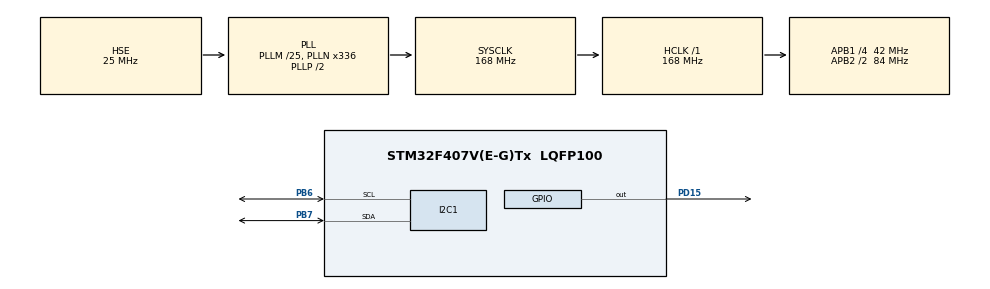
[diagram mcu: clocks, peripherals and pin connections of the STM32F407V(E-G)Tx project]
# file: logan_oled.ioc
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I2C1.I2C_Mode=I2C_Fast
Mcu.Family=STM32F4
Mcu.Name=STM32F407V(E-G)Tx
Mcu.Package=LQFP100
NVIC.PriorityGroup=NVIC_PRIORITYGROUP_4
PA13.Mode=Serial_Wire
PA13.Signal=SYS_JTMS-SWDIO
PA14.Mode=Serial_Wire
PA14.Signal=SYS_JTCK-SWCLK
PB6.Mode=I2C
PB6.Signal=I2C1_SCL
PB7.Mode=I2C
PB7.Signal=I2C1_SDA
PD15.Signal=GPIO_Output
PH0-OSC_IN.Mode=HSE-External-Oscillator
PH0-OSC_IN.Signal=RCC_OSC_IN
PH1-OSC_OUT.Mode=HSE-External-Oscillator
PH1-OSC_OUT.Signal=RCC_OSC_OUT
ProjectManager.HeapSize=0x200
ProjectManager.StackSize=0x400
ProjectManager.TargetToolchain=MDK-ARM V5.32
RCC.48MHZClocksFreq_Value=84000000
RCC.AHBFreq_Value=168000000
RCC.APB1CLKDivider=RCC_HCLK_DIV4
RCC.APB1Freq_Value=42000000
RCC.APB1TimFreq_Value=84000000
RCC.APB2CLKDivider=RCC_HCLK_DIV2
RCC.APB2Freq_Value=84000000
RCC.APB2TimFreq_Value=168000000
RCC.CortexFreq_Value=168000000
RCC.HCLKFreq_Value=168000000
RCC.HSE_VALUE=25000000
RCC.HSI_VALUE=16000000
RCC.LSE_VALUE=32768
RCC.PLLM=25
RCC.PLLN=336
RCC.PLLSourceVirtual=RCC_PLLSOURCE_HSE
RCC.SYSCLKFreq_VALUE=168000000
RCC.SYSCLKSource=RCC_SYSCLKSOURCE_PLLCLK
RCC.VCOOutputFreq_Value=336000000
board=custom

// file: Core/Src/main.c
/* USER CODE BEGIN Header */
/**
  ******************************************************************************
  * @file           : main.c
  * @brief          : Main program body
  ******************************************************************************
  * @attention
  *
  * Copyright (c) 2025 STMicroelectronics.
  * All rights reserved.
  *
  * This software is licensed under terms that can be found in the LICENSE file
  * in the root directory of this software component.
  * If no LICENSE file comes with this software, it is provided AS-IS.
  *
  ******************************************************************************
  */
/* USER CODE END Header */
#include "main.h"

/* USER CODE BEGIN Includes */
#include "stdio.h"
#include "font.h"
#include "oled_i2c.h"
/* USER CODE END Includes */

I2C_HandleTypeDef hi2c1;

void SystemClock_Config(void);
static void MX_GPIO_Init(void);
static void MX_I2C1_Init(void);

/* USER CODE BEGIN 0 */
const uint8_t smiley_face_128x64[1026] = {
    // H�ng 0-7
    0x00, 0x00, 0x00, 0x00, 0x00, 0x00, 0x00, 0x00, 0x00, 0x00, 0x00, 0x00, 0x00, 0x00, 0x00, 0x00,
    0x00, 0x00, 0x00, 0x00, 0x00, 0x00, 0x00, 0x00, 0x00, 0x00, 0x00, 0x00, 0x00, 0x00, 0x00, 0x00,
    0x00, 0x00, 0x00, 0x00, 0x00, 0x00, 0x00, 0x00, 0x00, 0x00, 0x00, 0x00, 0x00, 0x00, 0x00, 0x00,
    0x00, 0x00, 0x00, 0x00, 0x00, 0x00, 0x00, 0xFF, 0xFF, 0x00, 0x00, 0x00, 0x00, 0x00, 0x00, 0x00,
    0x00, 0x00, 0x00, 0x00, 0x00, 0x00, 0xFF, 0xFF, 0xFF, 0xFF, 0x00, 0x00, 0x00, 0x00, 0x00, 0x00,
    0x00, 0x00, 0x00, 0x00, 0x00, 0xFF, 0xFF, 0xFF, 0xFF, 0xFF, 0xFF, 0x00, 0x00, 0x00, 0x00, 0x00,
    0x00, 0x00, 0x00, 0x00, 0xFF, 0xFF, 0xFF, 0xFF, 0xFF, 0xFF, 0xFF, 0xFF, 0x00, 0x00, 0x00, 0x00,
    0x00, 0x00, 0x00, 0xFF, 0xFF, 0xFF, 0xFF, 0xFF, 0xFF, 0xFF, 0xFF, 0xFF, 0xFF, 0x00, 0x00, 0x00,

    // H�ng 8-15
    0x00, 0x00, 0x00, 0xFF, 0xFF, 0xFF, 0xFF, 0xFF, 0xFF, 0xFF, 0xFF, 0xFF, 0xFF, 0x00, 0x00, 0x00,
    0x00, 0x00, 0xFF, 0xFF, 0xFF, 0xFF, 0xFF, 0xFF, 0xFF, 0xFF, 0xFF, 0xFF, 0xFF, 0xFF, 0x00, 0x00,
    0x00, 0x00, 0xFF, 0xFF, 0xFF, 0xFF, 0xFF, 0xFF, 0xFF, 0xFF, 0xFF, 0xFF, 0xFF, 0xFF, 0x00, 0x00,
    0x00, 0xFF, 0xFF, 0xFF, 0xFF, 0xFF, 0xFF, 0xFF, 0xFF, 0xFF, 0xFF, 0xFF, 0xFF, 0xFF, 0xFF, 0x00,
    0x00, 0xFF, 0xFF, 0xFF, 0xFF, 0xFF, 0xFF, 0xFF, 0xFF, 0xFF, 0xFF, 0xFF, 0xFF, 0xFF, 0xFF, 0x00,
    0x00, 0xFF, 0xFF, 0xFF, 0xFF, 0xFF, 0xFF, 0xFF, 0xFF, 0xFF, 0xFF, 0xFF, 0xFF, 0xFF, 0xFF, 0x00,
    0x00, 0xFF, 0xFF, 0xFF, 0xFF, 0xFF, 0xFF, 0xFF, 0xFF, 0xFF, 0xFF, 0xFF, 0xFF, 0xFF, 0xFF, 0x00,
    0x00, 0xFF, 0xFF, 0xFF, 0xFF, 0xFF, 0xFF, 0xFF, 0xFF, 0xFF, 0xFF, 0xFF, 0xFF, 0xFF, 0xFF, 0x00,

    // H�ng 16-23 (Th�m m?t)
    0x00, 0xFF, 0xFF, 0xFF, 0xFF, 0xFF, 0xFF, 0xF0, 0x0F, 0xFF, 0xFF, 0xFF, 0xFF, 0xFF, 0xFF, 0x00,
    0x00, 0xFF, 0xFF, 0xFF, 0xFF, 0xFF, 0xF0, 0x00, 0x00, 0x0F, 0xFF, 0xFF, 0xFF, 0xFF, 0xFF, 0x00,
    0x00, 0xFF, 0xFF, 0xFF, 0xFF, 0xFF, 0xF0, 0x00, 0x00, 0x0F, 0xFF, 0xFF, 0xFF, 0xFF, 0xFF, 0x00,
    0x00, 0xFF, 0xFF, 0xFF, 0xFF, 0xFF, 0xF0, 0x00, 0x00, 0x0F, 0xFF, 0xFF, 0xFF, 0xFF, 0xFF, 0x00,
    0x00, 0xFF, 0xFF, 0xFF, 0xFF, 0xFF, 0xFF, 0xF0, 0x0F, 0xFF, 0xFF, 0xFF, 0xFF, 0xFF, 0xFF, 0x00,
    0x00, 0xFF, 0xFF, 0xFF, 0xFF, 0xFF, 0xFF, 0xFF, 0xFF, 0xFF, 0xFF, 0xFF, 0xFF, 0xFF, 0xFF, 0x00,
    0x00, 0xFF, 0xFF, 0xFF, 0xFF, 0xFF, 0xFF, 0xFF, 0xFF, 0xFF, 0xFF, 0xFF, 0xFF, 0xFF, 0xFF, 0x00,
    0x00, 0xFF, 0xFF, 0xFF, 0xFF, 0xFF, 0xFF, 0xFF, 0xFF, 0xFF, 0xFF, 0xFF, 0xFF, 0xFF, 0xFF, 0x00,

    // H�ng 24-31 (Th�m m?t)
    0x00, 0xFF, 0xFF, 0xFF, 0xFF, 0xFF, 0xFF, 0xFF, 0xFF, 0xFF, 0xFF, 0xFF, 0xFF, 0xFF, 0xFF, 0x00,
    0x00, 0xFF, 0xFF, 0xFF, 0xFF, 0xFF, 0xFF, 0xFF, 0xFF, 0xFF, 0xFF, 0xFF, 0xFF, 0xFF, 0xFF, 0x00,
    0x00, 0xFF, 0xFF, 0xFF, 0xFF, 0xFF, 0xFF, 0xFF, 0xFF, 0xFF, 0xFF, 0xFF, 0xFF, 0xFF, 0xFF, 0x00,
    0x00, 0xFF, 0xFF, 0xFF, 0xFF, 0xFF, 0xFF, 0xFF, 0xFF, 0xFF, 0xFF, 0xFF, 0xFF, 0xFF, 0xFF, 0x00,
    0x00, 0xFF, 0xFF, 0xFF, 0xFF, 0xFF, 0xFF, 0xFF, 0xFF, 0xFF, 0xFF, 0xFF, 0xFF, 0xFF, 0xFF, 0x00,
    0x00, 0xFF, 0xFF, 0xFF, 0xFF, 0xFF, 0xFF, 0xFF, 0xFF, 0xFF, 0xFF, 0xFF, 0xFF, 0xFF, 0xFF, 0x00,
    0x00, 0xFF, 0xFF, 0xFF, 0xFF, 0xFF, 0xFF, 0xFF, 0xFF, 0xFF, 0xFF, 0xFF, 0xFF, 0xFF, 0xFF, 0x00,
    0x00, 0xFF, 0xFF, 0xFF, 0xFF, 0xFF, 0xFF, 0xFF, 0xFF, 0xFF, 0xFF, 0xFF, 0xFF, 0xFF, 0xFF, 0x00,

    // H�ng 32-39 (Th�m mi?ng cu?i)
    0x00, 0xFF, 0xFF, 0xFF, 0xFF, 0xFF, 0xFF, 0xFF, 0xFF, 0xFF, 0xFF, 0xFF, 0xFF, 0xFF, 0xFF, 0x00,
    0x00, 0xFF, 0xFF, 0xFF, 0xFF, 0xFF, 0xFF, 0xFF, 0xFF, 0xFF, 0xFF, 0xFF, 0xFF, 0xFF, 0xFF, 0x00,
    0x00, 0xFF, 0xFF, 0xFF, 0xFF, 0xFF, 0xFF, 0xFF, 0xFF, 0xFF, 0xFF, 0xFF, 0xFF, 0xFF, 0xFF, 0x00,
    0x00, 0xFF, 0xFF, 0xFF, 0xFF, 0xFF, 0xFF, 0x00, 0x00, 0xFF, 0xFF, 0xFF, 0xFF, 0xFF, 0xFF, 0x00,
    0x00, 0xFF, 0xFF, 0xFF, 0xFF, 0xFF, 0xF0, 0x00, 0x00, 0x0F, 0xFF, 0xFF, 0xFF, 0xFF, 0xFF, 0x00,
    0x00, 0xFF, 0xFF, 0xFF, 0xFF, 0xFF, 0x00, 0x00, 0x00, 0x00, 0xFF, 0xFF, 0xFF, 0xFF, 0xFF, 0x00,
    0x00, 0xFF, 0xFF, 0xFF, 0xFF, 0xF0, 0x00, 0x00, 0x00, 0x00, 0x0F, 0xFF, 0xFF, 0xFF, 0xFF, 0x00,
    0x00, 0xFF, 0xFF, 0xFF, 0xFF, 0xF0, 0x00, 0x00, 0x00, 0x00, 0x0F, 0xFF, 0xFF, 0xFF, 0xFF, 0x00,

    // H�ng 40-47
    0x00, 0xFF, 0xFF, 0xFF, 0xFF, 0xFF, 0x00, 0x00, 0x00, 0x00, 0xFF, 0xFF, 0xFF, 0xFF, 0xFF, 0x00,
    0x00, 0xFF, 0xFF, 0xFF, 0xFF, 0xFF, 0xF0, 0x00, 0x00, 0x0F, 0xFF, 0xFF, 0xFF, 0xFF, 0xFF, 0x00,
    0x00, 0xFF, 0xFF, 0xFF, 0xFF, 0xFF, 0xFF, 0x00, 0x00, 0xFF, 0xFF, 0xFF, 0xFF, 0xFF, 0xFF, 0x00,
    0x00, 0xFF, 0xFF, 0xFF, 0xFF, 0xFF, 0xFF, 0xFF, 0xFF, 0xFF, 0xFF, 0xFF, 0xFF, 0xFF, 0xFF, 0x00,
    0x00, 0xFF, 0xFF, 0xFF, 0xFF, 0xFF, 0xFF, 0xFF, 0xFF, 0xFF, 0xFF, 0xFF, 0xFF, 0xFF, 0xFF, 0x00,
    0x00, 0xFF, 0xFF, 0xFF, 0xFF, 0xFF, 0xFF, 0xFF, 0xFF, 0xFF, 0xFF, 0xFF, 0xFF, 0xFF, 0xFF, 0x00,
    0x00, 0xFF, 0xFF, 0xFF, 0xFF, 0xFF, 0xFF, 0xFF, 0xFF, 0xFF, 0xFF, 0xFF, 0xFF, 0xFF, 0xFF, 0x00,
    0x00, 0xFF, 0xFF, 0xFF, 0xFF, 0xFF, 0xFF, 0xFF, 0xFF, 0xFF, 0xFF, 0xFF, 0xFF, 0xFF, 0xFF, 0x00,

    // H�ng 48-55
    0x00, 0xFF, 0xFF, 0xFF, 0xFF, 0xFF, 0xFF, 0xFF, 0xFF, 0xFF, 0xFF, 0xFF, 0xFF, 0xFF, 0xFF, 0x00,
    0x00, 0xFF, 0xFF, 0xFF, 0xFF, 0xFF, 0xFF, 0xFF, 0xFF, 0xFF, 0xFF, 0xFF, 0xFF, 0xFF, 0xFF, 0x00,
    0x00, 0x00, 0xFF, 0xFF, 0xFF, 0xFF, 0xFF, 0xFF, 0xFF, 0xFF, 0xFF, 0xFF, 0xFF, 0xFF, 0x00, 0x00,
    0x00, 0x00, 0xFF, 0xFF, 0xFF, 0xFF, 0xFF, 0xFF, 0xFF, 0xFF, 0xFF, 0xFF, 0xFF, 0xFF, 0x00, 0x00,
    0x00, 0x00, 0x00, 0xFF, 0xFF, 0xFF, 0xFF, 0xFF, 0xFF, 0xFF, 0xFF, 0xFF, 0xFF, 0x00, 0x00, 0x00,
    0x00, 0x00, 0x00, 0xFF, 0xFF, 0xFF, 0xFF, 0xFF, 0xFF, 0xFF, 0xFF, 0xFF, 0xFF, 0x00, 0x00, 0x00,
    0x00, 0x00, 0x00, 0x00, 0xFF, 0xFF, 0xFF, 0xFF, 0xFF, 0xFF, 0xFF, 0xFF, 0x00, 0x00, 0x00, 0x00,
    0x00,0x00, 0x00, 0x00, 0x00, 0xFF, 0xFF, 0xFF, 0xFF, 0xFF, 0xFF, 0xFF, 0xFF, 0x00, 0x00, 0x00, 0x00,

    // H�ng 56-63
    0x00, 0x00, 0x00, 0x00, 0x00, 0xFF, 0xFF, 0xFF, 0xFF, 0xFF, 0xFF, 0x00, 0x00, 0x00, 0x00, 0x00,
    0x00, 0x00, 0x00, 0x00, 0x00, 0x00, 0xFF, 0xFF, 0xFF, 0xFF, 0x00, 0x00, 0x00, 0x00, 0x00, 0x00,
    0x00, 0x00, 0x00, 0x00, 0x00, 0x00, 0x00, 0xFF, 0xFF, 0x00, 0x00, 0x00, 0x00, 0x00, 0x00, 0x00,
    0x00, 0x00, 0x00, 0x00, 0x00, 0x00, 0x00, 0x00, 0x00, 0x00, 0x00, 0x00, 0x00, 0x00, 0x00, 0x00,
    0x00, 0x00, 0x00, 0x00, 0x00, 0x00, 0x00, 0x00, 0x00, 0x00, 0x00, 0x00, 0x00, 0x00, 0x00, 0x00,
    0x00, 0x00, 0x00, 0x00, 0x00, 0x00, 0x00, 0x00, 0x00, 0x00, 0x00, 0x00, 0x00, 0x00, 0x00, 0x00,
    0x00, 0x00, 0x00, 0x00, 0x00, 0x00, 0x00, 0x00, 0x00, 0x00, 0x00, 0x00, 0x00, 0x00, 0x00, 0x00,
    0x00, 0x00, 0x00, 0x00, 0x00, 0x00, 0x00, 0x00, 0x00, 0x00, 0x00, 0x00, 0x00, 0x00, 0x00, 0x00
};

const uint8_t cat[10000] = {
	0xff,0xff,0xff,0xff,0xff,0xff,0xff,0xff,0xff,0xff,0xff,0xff,0xff,0xff,0xff,0xff
,0xff,0xff,0xff,0xff,0xff,0xff,0xff,0xff,0xff,0xff,0xff,0xff,0xff,0xff,0xff,0xff
,0xff,0xff,0xff,0xff,0xff,0xff,0xff,0xff,0xff,0xff,0xff,0xff,0xff,0xff,0xff,0xff
,0xff,0xff,0xff,0xff,0xff,0xff,0xff,0xfc,0x1f,0xff,0xff,0xff,0xff,0xff,0xff,0xff
,0xff,0xff,0xff,0xff,0xff,0xff,0xfc,0x00,0x00,0x1f,0xff,0xff,0xff,0xff,0xff,0xff
,0xff,0xff,0xff,0xff,0xff,0xff,0xc0,0x7f,0xfe,0x03,0xff,0xff,0xff,0xff,0xff,0xff
,0xff,0xff,0xff,0xff,0xff,0xff,0x07,0xff,0xff,0xf0,0x7f,0xff,0xff,0xff,0xff,0xff
,0xff,0xff,0xff,0xff,0xff,0xfc,0x3f,0xff,0xff,0xfe,0x1f,0xff,0xff,0xff,0xff,0xff
,0xff,0xff,0xff,0xff,0xff,0xf1,0xff,0xff,0xff,0xff,0x87,0xff,0xff,0xff,0xff,0xff
,0xff,0xff,0xff,0xff,0xff,0xe3,0xff,0xff,0xff,0xff,0xe3,0xff,0xff,0xff,0xff,0xff
,0xff,0xff,0xff,0xff,0xff,0xc7,0xff,0xff,0xff,0xff,0xf1,0xff,0xff,0xff,0xff,0xff
,0xff,0xff,0xff,0xff,0xff,0x8f,0xff,0xff,0xff,0xff,0xf8,0xff,0xff,0xff,0xff,0xff
,0xff,0xff,0xff,0xff,0xff,0x1f,0xff,0xff,0xff,0xff,0xfc,0x7f,0xff,0xff,0xff,0xff
,0xff,0xff,0xff,0xff,0xff,0x3f,0xff,0xff,0xff,0xff,0xfe,0x7f,0xff,0xff,0xff,0xff
,0xff,0xff,0xff,0xff,0xff,0x3f,0xff,0xff,0xff,0xff,0xfe,0x3f,0xff,0xff,0xff,0xff
,0xff,0xff,0xff,0xff,0xfe,0x3f,0xff,0xff,0xff,0xff,0xfe,0x3f,0xff,0xff,0xff,0xff
,0xff,0xff,0xff,0xff,0xff,0x3f,0xf0,0x1f,0xfc,0x07,0xfe,0x7f,0xff,0xff,0xff,0xff
,0xff,0xff,0xff,0xff,0xff,0x3f,0xc0,0x0f,0xf0,0x01,0xfe,0x7f,0xff,0xff,0xff,0xff
,0xff,0xff,0xef,0xff,0xff,0x1f,0xc0,0x07,0xf0,0x01,0xfc,0x7f,0xff,0xff,0xff,0xff
,0xff,0xff,0xff,0xff,0xff,0x8f,0xc0,0x07,0xf0,0x01,0xf8,0xff,0xff,0xff,0xff,0xff
,0xff,0xff,0xff,0xff,0xff,0xc7,0xc0,0x0f,0xf8,0x03,0xf1,0xff,0xff,0xff,0xff,0xff
,0xff,0xff,0xff,0xff,0xff,0xe3,0xe0,0x1f,0xfc,0x07,0xe3,0xff,0xff,0xff,0xff,0xff
,0xff,0xff,0xff,0xff,0xff,0xf1,0xff,0xf8,0x0f,0xff,0x87,0xff,0xff,0xff,0xff,0xff
,0xff,0xff,0xff,0xff,0xff,0xfc,0x3f,0xf8,0x0f,0xfe,0x1f,0xff,0xff,0xff,0xff,0xff
,0xff,0xff,0xff,0xff,0xff,0xff,0x07,0xfc,0x1f,0xf0,0x7f,0xff,0xff,0xff,0xff,0xff
,0xff,0xff,0xff,0xff,0xff,0xff,0xc3,0xfe,0x3f,0xe3,0xff,0xff,0xff,0xff,0xff,0xff
,0xff,0xff,0xff,0xff,0xff,0xff,0xe3,0xfe,0x7f,0xe7,0xff,0xff,0xff,0xff,0xff,0xff
,0xff,0xff,0xff,0xff,0xff,0xff,0xe3,0xff,0xff,0xc7,0xff,0xff,0xff,0xff,0xff,0xff
,0xff,0xff,0xff,0xff,0xff,0xff,0xe3,0xff,0xff,0xc7,0xff,0xff,0xff,0xff,0xff,0xff
,0xff,0xff,0xff,0xff,0xff,0xff,0xe3,0xdd,0xdd,0xc7,0xff,0xff,0xff,0xff,0xff,0xff
,0xff,0xff,0xff,0xff,0xff,0xff,0xe0,0x00,0x00,0x07,0xff,0xff,0xff,0xff,0xff,0xff
,0xff,0xff,0xff,0xff,0xff,0xff,0xf4,0xc4,0x00,0x0f,0xff,0xff,0xff,0xff,0xff,0xff
,0xff,0xff,0xff,0xff,0xff,0xff,0xfc,0xee,0x77,0x3f,0xff,0xff,0xff,0xff,0xff,0xff
,0xff,0xff,0xff,0xff,0xff,0xff,0xff,0xef,0x77,0xbf,0xff,0xff,0xff,0xff,0xff,0xff
,0xff,0xff,0xff,0xff,0xff,0xff,0xff,0xff,0xff,0xff,0xff,0xff,0xff,0xff,0xff,0xff
,0xff,0xff,0xff,0xff,0xff,0xc0,0xff,0x0f,0xe3,0xe1,0xe0,0x1f,0xff,0xff,0xff,0xff
,0xff,0xff,0xff,0xff,0xff,0x84,0x3f,0x03,0xe0,0xc1,0xe1,0xff,0xff,0xff,0xff,0xff
,0xff,0xff,0xff,0xff,0xff,0x86,0x3e,0x03,0xe0,0xc1,0xe3,0xff,0xff,0xff,0xff,0xff
,0xff,0xff,0xff,0xff,0xff,0x8f,0xfe,0x03,0xe0,0x01,0xe0,0x3f,0xff,0xff,0xff,0xff
,0xff,0xff,0xff,0xff,0xff,0x8c,0x3c,0x63,0xe0,0x01,0xe3,0xff,0xff,0x7f,0xff,0xff
,0xff,0xff,0xff,0xff,0xff,0x8e,0x3c,0x01,0xc0,0x01,0xc3,0xff,0xff,0xff,0xff,0xff
,0xff,0xff,0xff,0xff,0xff,0x80,0x3c,0x61,0xe1,0x00,0xe0,0x1f,0xff,0xff,0xff,0xff
,0xff,0xff,0xff,0xff,0xff,0xe0,0x7c,0xfb,0xfb,0x98,0xff,0xff,0xff,0xff,0xff,0xff
,0xff,0xff,0xff,0xff,0xff,0xff,0xff,0xff,0xff,0xff,0xff,0xff,0xff,0xff,0xff,0xff
,0xff,0xff,0xf8,0x03,0xff,0xff,0xff,0xff,0xfe,0x00,0x00,0xff,0x00,0x0f,0xff,0xff
,0xff,0xff,0xc0,0x00,0x3f,0xc0,0x3f,0x80,0xfc,0x00,0x00,0xfe,0x00,0x00,0x7f,0xff
,0xff,0xff,0xc0,0x00,0x0f,0xe0,0x3f,0x80,0xfe,0x01,0xff,0xff,0x00,0x00,0x3f,0xff
,0xff,0xff,0x00,0xf0,0x1f,0xe0,0x1f,0x01,0xfe,0x01,0xff,0xfe,0x01,0xe0,0x1f,0xff
,0xff,0xff,0x00,0xf0,0x0f,0xf0,0x1f,0x01,0xff,0x01,0xff,0xfe,0x01,0xe0,0x1f,0xff
,0xff,0xff,0x00,0xf0,0x0f,0xf0,0x1f,0x03,0xfc,0x03,0xff,0xfe,0x01,0xe0,0x1f,0xff
,0xff,0xff,0x01,0xf0,0x0f,0xf0,0x1e,0x03,0xfc,0x00,0xff,0xfe,0x01,0xe0,0x3f,0xff
,0xff,0xff,0x00,0xf8,0x0f,0xf8,0x0e,0x03,0xfc,0x00,0x03,0xfe,0x00,0x00,0xff,0xff
,0xff,0xff,0x00,0xf0,0x0f,0xf8,0x0e,0x03,0xfc,0x00,0x03,0xfe,0x00,0x00,0xff,0xff
,0xff,0xff,0x00,0xf0,0x0f,0xf8,0x04,0x07,0xfc,0x03,0xff,0xfe,0x00,0x00,0x3f,0xff
,0xff,0xff,0x00,0xf0,0x0f,0xfc,0x00,0x07,0xfe,0x03,0xff,0xfe,0x0f,0xe0,0x1f,0xff
,0xff,0xff,0x00,0xf0,0x0f,0xfc,0x00,0x0f,0xfc,0x03,0xff,0xfe,0x01,0xe0,0x1f,0xff
,0xff,0xff,0x00,0xf0,0x0f,0xfe,0x00,0x0f,0xf8,0x07,0xff,0xfe,0x01,0xe0,0x1f,0xff
,0xff,0xff,0xe0,0x10,0x03,0xfe,0x00,0x0f,0xfe,0x00,0x00,0x7f,0x80,0x78,0x07,0xff
,0xff,0xff,0xf0,0x00,0x0f,0xff,0xc0,0x07,0xfe,0x00,0x00,0x7f,0x80,0x7c,0x07,0xff
,0xff,0xff,0xfe,0x00,0x3f,0xff,0xc0,0x07,0xff,0xff,0xff,0xff,0xc0,0x7c,0x07,0xff
,0xff,0xff,0xff,0xff,0xff,0xff,0xff,0xff,0xff,0xff,0xff,0xff,0xff,0xff,0xff,0xff
,0xff,0xff,0xff,0xff,0xff,0xff,0xff,0xff,0xff,0xff,0xff,0xff,0xff,0xff,0xff,0xff
,0xff,0xff,0xff,0xff,0xff,0xff,0xff,0xff,0xff,0xff,0xff,0xff,0xff,0xff,0xff,0xff
,0xff,0xff,0xff,0xff,0xff,0xff,0xff,0xff,0xff,0xff,0xff,0xff,0xff,0xff,0xff,0xff
};
const uint8_t star[128] = {
    0x00, 0x00, 0x00, 0x00, 0x00, 0x00, 0x00, 0x00, 0x00, 0x00, 0x00, 0x00, 0x00, 0x00, 0x00, 0x00,
    0x00, 0x00, 0x00, 0x00, 0x00, 0x00, 0x03, 0xC0, 0x03, 0xC0, 0x00, 0x00, 0x00, 0x00, 0x00, 0x00,
    0x00, 0x00, 0x00, 0x00, 0x07, 0xE0, 0x1F, 0xF8, 0x1F, 0xF8, 0x07, 0xE0, 0x00, 0x00, 0x00, 0x00,
    0x00, 0x00, 0x00, 0x00, 0x0F, 0xF0, 0xFF, 0xFF, 0xFF, 0xFF, 0x0F, 0xF0, 0x00, 0x00, 0x00, 0x00,
    0x00, 0x00, 0x00, 0x00, 0x1F, 0xF8, 0x3F, 0xFC, 0x3F, 0xFC, 0x1F, 0xF8, 0x00, 0x00, 0x00, 0x00,
    0x00, 0x00, 0x00, 0x00, 0x3F, 0xFC, 0x07, 0xE0, 0x07, 0xE0, 0x3F, 0xFC, 0x00, 0x00, 0x00, 0x00,
    0x00, 0x00, 0x00, 0x00, 0x07, 0xE0, 0x1F, 0xF8, 0x1F, 0xF8, 0x07, 0xE0, 0x00, 0x00, 0x00, 0x00,
    0x00, 0x00, 0x00, 0x00, 0x00, 0x00, 0x03, 0xC0, 0x03, 0xC0, 0x00, 0x00, 0x00, 0x00, 0x00, 0x00
};
const uint8_t heart_16x16[32] = {
    0x00, 0x00, 0x00, 0x00, 0x0C, 0x30, 0x1E, 0x78,
    0x3F, 0xFC, 0x7F, 0xFE, 0xFF, 0xFF, 0xFF, 0xFF,
    0xFF, 0xFF, 0x7F, 0xFE, 0x3F, 0xFC, 0x1F, 0xF8,
    0x0F, 0xF0, 0x07, 0xE0, 0x03, 0xC0, 0x01, 0x80
};
/* USER CODE END 0 */

int main(void)
{

  /* MCU Configuration--------------------------------------------------------*/

  /* Reset of all peripherals, Initializes the Flash interface and the Systick. */
  HAL_Init();

  /* Configure the system clock */
  SystemClock_Config();

  /* Initialize all configured peripherals */
  MX_GPIO_Init();
  MX_I2C1_Init();
  /* USER CODE BEGIN 2 */
	SSD1306_Init();
  char snum[5];

  SSD1306_GotoXY (0,0);
//	SSD1306_DrawBitmap(48, 16, cat, 32, 32, 1);  // V? bitmap ? t?a d? (48, 16), k�ch thu?c 32x32
	HAL_Delay(1000);
  SSD1306_Puts ("LOGAN x ", &Font_11x18, 1);
  SSD1306_GotoXY (0, 30);
  SSD1306_Puts ("HIEU", &Font_11x18, 1);
  SSD1306_UpdateScreen();
  HAL_Delay (1000);

  SSD1306_ScrollRight(0,7);
  HAL_Delay(1000);
  SSD1306_ScrollLeft(0,7);
  HAL_Delay(1000);
  SSD1306_Stopscroll();
  SSD1306_Clear();
	// Hi?n th? h�nh ?nh m?t cu?i
  SSD1306_Clear();  // X�a m�n h�nh tru?c khi v? h�nh
//  SSD1306_DrawBitmap(48, 16, cat, 32, 32, 1);  // V? bitmap ? t?a d? (48, 16), k�ch thu?c 32x32
	SSD1306_GotoXY (35,0);
	SSD1306_Puts ("SIU", &Font_11x18, 1);
  SSD1306_UpdateScreen();
  HAL_Delay(3000);  // Hi?n th? h�nh ?nh trong 3 gi�y
	SSD1306_Clear();
  SSD1306_GotoXY (35,0);
  SSD1306_Puts ("SCORE", &Font_11x18, 1);
  /* USER CODE END 2 */

  /* Infinite loop */
  while (1)
  {

    /* USER CODE BEGIN 3 */
		for ( int x = 1; x <= 10000 ; x++ )
	{
		sprintf(snum, "%d", x);
		SSD1306_GotoXY (0, 30);
		SSD1306_Puts ("             ", &Font_16x26, 1);
		SSD1306_UpdateScreen();
		if(x < 10) {
			SSD1306_GotoXY (53, 30);  // 1 DIGIT
		}
		else if (x < 100 ) {
			SSD1306_GotoXY (45, 30);  // 2 DIGITS
		}
		else if (x < 1000 ) {
			SSD1306_GotoXY (37, 30);  // 3 DIGITS
		}
		else {
			SSD1306_GotoXY (30, 30);  // 4 DIGIS
		}
		SSD1306_Puts (snum, &Font_16x26, 1);
		SSD1306_UpdateScreen();
		HAL_Delay (500);
	    }
  }
  /* USER CODE END 3 */
}

void SystemClock_Config(void)
{
  RCC_OscInitTypeDef RCC_OscInitStruct = {0};
  RCC_ClkInitTypeDef RCC_ClkInitStruct = {0};

  /** Configure the main internal regulator output voltage
  */
  __HAL_RCC_PWR_CLK_ENABLE();
  __HAL_PWR_VOLTAGESCALING_CONFIG(PWR_REGULATOR_VOLTAGE_SCALE1);

  /** Initializes the RCC Oscillators according to the specified parameters
  * in the RCC_OscInitTypeDef structure.
  */
  RCC_OscInitStruct.OscillatorType = RCC_OSCILLATORTYPE_HSE;
  RCC_OscInitStruct.HSEState = RCC_HSE_ON;
  RCC_OscInitStruct.PLL.PLLState = RCC_PLL_ON;
  RCC_OscInitStruct.PLL.PLLSource = RCC_PLLSOURCE_HSE;
  RCC_OscInitStruct.PLL.PLLM = 25;
  RCC_OscInitStruct.PLL.PLLN = 336;
  RCC_OscInitStruct.PLL.PLLP = RCC_PLLP_DIV2;
  RCC_OscInitStruct.PLL.PLLQ = 4;
  if (HAL_RCC_OscConfig(&RCC_OscInitStruct) != HAL_OK)
  {
    Error_Handler();
  }

  /** Initializes the CPU, AHB and APB buses clocks
  */
  RCC_ClkInitStruct.ClockType = RCC_CLOCKTYPE_HCLK|RCC_CLOCKTYPE_SYSCLK
                              |RCC_CLOCKTYPE_PCLK1|RCC_CLOCKTYPE_PCLK2;
  RCC_ClkInitStruct.SYSCLKSource = RCC_SYSCLKSOURCE_PLLCLK;
  RCC_ClkInitStruct.AHBCLKDivider = RCC_SYSCLK_DIV1;
  RCC_ClkInitStruct.APB1CLKDivider = RCC_HCLK_DIV4;
  RCC_ClkInitStruct.APB2CLKDivider = RCC_HCLK_DIV2;

  if (HAL_RCC_ClockConfig(&RCC_ClkInitStruct, FLASH_LATENCY_5) != HAL_OK)
  {
    Error_Handler();
  }
}

static void MX_I2C1_Init(void)
{

  hi2c1.Instance = I2C1;
  hi2c1.Init.ClockSpeed = 400000;
  hi2c1.Init.DutyCycle = I2C_DUTYCYCLE_2;
  hi2c1.Init.OwnAddress1 = 0;
  hi2c1.Init.AddressingMode = I2C_ADDRESSINGMODE_7BIT;
  hi2c1.Init.DualAddressMode = I2C_DUALADDRESS_DISABLE;
  hi2c1.Init.OwnAddress2 = 0;
  hi2c1.Init.GeneralCallMode = I2C_GENERALCALL_DISABLE;
  hi2c1.Init.NoStretchMode = I2C_NOSTRETCH_DISABLE;
  if (HAL_I2C_Init(&hi2c1) != HAL_OK)
  {
    Error_Handler();
  }

}

static void MX_GPIO_Init(void)
{
  GPIO_InitTypeDef GPIO_InitStruct = {0};

  /* GPIO Ports Clock Enable */
  __HAL_RCC_GPIOH_CLK_ENABLE();
  __HAL_RCC_GPIOD_CLK_ENABLE();
  __HAL_RCC_GPIOA_CLK_ENABLE();
  __HAL_RCC_GPIOB_CLK_ENABLE();

  /*Configure GPIO pin Output Level */
  HAL_GPIO_WritePin(GPIOD, GPIO_PIN_15, GPIO_PIN_RESET);

  /*Configure GPIO pin : PD15 */
  GPIO_InitStruct.Pin = GPIO_PIN_15;
  GPIO_InitStruct.Mode = GPIO_MODE_OUTPUT_PP;
  GPIO_InitStruct.Pull = GPIO_NOPULL;
  GPIO_InitStruct.Speed = GPIO_SPEED_FREQ_LOW;
  HAL_GPIO_Init(GPIOD, &GPIO_InitStruct);

}

void Error_Handler(void)
{
  __disable_irq();
  while (1)
  {
  }
}
